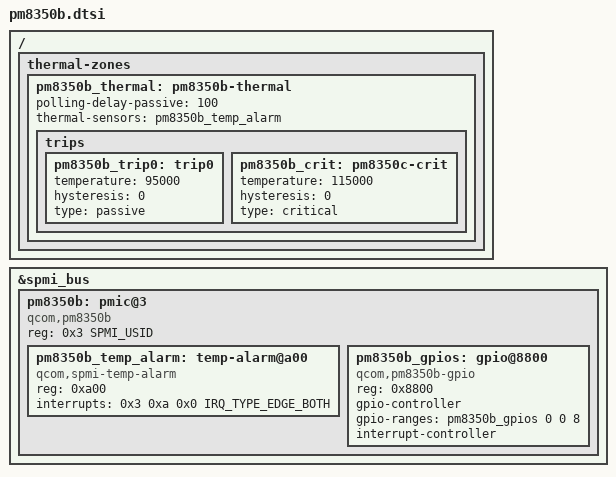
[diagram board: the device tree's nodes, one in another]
// SPDX-License-Identifier: BSD-3-Clause
/*
 * Copyright (c) 2021, Linaro Limited
 */

#include <dt-bindings/interrupt-controller/irq.h>
#include <dt-bindings/spmi/spmi.h>

/ {
	thermal-zones {
		pm8350b_thermal: pm8350b-thermal {
			polling-delay-passive = <100>;

			thermal-sensors = <&pm8350b_temp_alarm>;

			trips {
				pm8350b_trip0: trip0 {
					temperature = <95000>;
					hysteresis = <0>;
					type = "passive";
				};

				pm8350b_crit: pm8350c-crit {
					temperature = <115000>;
					hysteresis = <0>;
					type = "critical";
				};
			};
		};
	};
};

&spmi_bus {
	pm8350b: pmic@3 {
		compatible = "qcom,pm8350b", "qcom,spmi-pmic";
		reg = <0x3 SPMI_USID>;
		#address-cells = <1>;
		#size-cells = <0>;

		pm8350b_temp_alarm: temp-alarm@a00 {
			compatible = "qcom,spmi-temp-alarm";
			reg = <0xa00>;
			interrupts = <0x3 0xa 0x0 IRQ_TYPE_EDGE_BOTH>;
			#thermal-sensor-cells = <0>;
		};

		pm8350b_gpios: gpio@8800 {
			compatible = "qcom,pm8350b-gpio", "qcom,spmi-gpio";
			reg = <0x8800>;
			gpio-controller;
			gpio-ranges = <&pm8350b_gpios 0 0 8>;
			#gpio-cells = <2>;
			interrupt-controller;
			#interrupt-cells = <2>;
		};
	};
};
